AUTOSAR XML (schema 4-0-3)
package /ComponentTypes
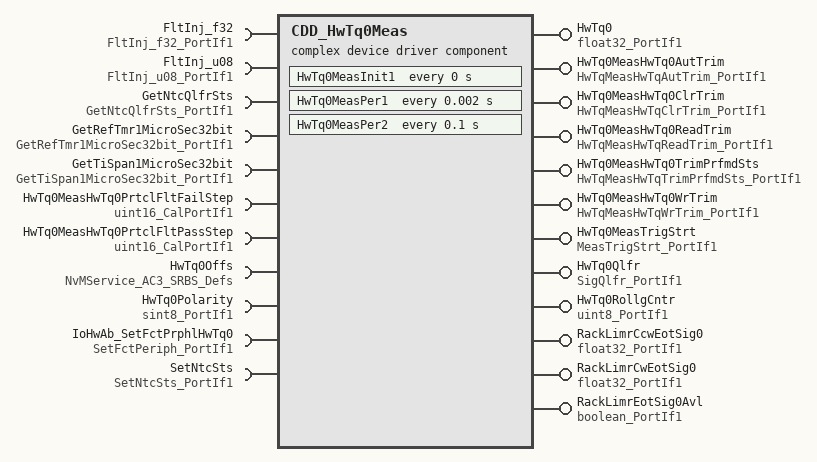
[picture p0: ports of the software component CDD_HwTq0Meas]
  complex device driver sw component type CDD_HwTq0Meas
    12 x provide port:
      HwTq0: nonqueued-sender-com-spec{data-element=Val, init-value=0}, provided-interface=float32_PortIf1
      HwTq0MeasHwTq0AutTrim: server-com-spec{operation=Oper, queue-length=1}, provided-interface=HwTqMeasHwTqAutTrim_PortIf1
      HwTq0MeasHwTq0ClrTrim: server-com-spec{operation=Oper, queue-length=1}, provided-interface=HwTqMeasHwTqClrTrim_PortIf1
      HwTq0MeasHwTq0ReadTrim: server-com-spec{operation=Oper, queue-length=1}, provided-interface=HwTqMeasHwTqReadTrim_PortIf1
      HwTq0MeasHwTq0TrimPrfmdSts: server-com-spec{operation=Oper, queue-length=1}, provided-interface=HwTqMeasHwTqTrimPrfmdSts_PortIf1
      HwTq0MeasHwTq0WrTrim: server-com-spec{operation=Oper, queue-length=1}, provided-interface=HwTqMeasHwTqWrTrim_PortIf1
      HwTq0MeasTrigStrt: server-com-spec{operation=Oper, queue-length=1}, provided-interface=MeasTrigStrt_PortIf1
      HwTq0Qlfr: nonqueued-sender-com-spec{data-element=Val, init-value=0}, provided-interface=SigQlfr_PortIf1
      HwTq0RollgCntr: nonqueued-sender-com-spec{data-element=Val, init-value=0}, provided-interface=uint8_PortIf1
      RackLimrCcwEotSig0: nonqueued-sender-com-spec{data-element=Val, init-value=0}, provided-interface=float32_PortIf1
      RackLimrCwEotSig0: nonqueued-sender-com-spec{data-element=Val, init-value=0}, provided-interface=float32_PortIf1
      RackLimrEotSig0Avl: nonqueued-sender-com-spec{data-element=Logl, init-value=0}, provided-interface=boolean_PortIf1
    11 x require port:
      FltInj_f32: required-interface=FltInj_f32_PortIf1
      FltInj_u08: required-interface=FltInj_u08_PortIf1
      GetNtcQlfrSts: required-interface=GetNtcQlfrSts_PortIf1
      GetRefTmr1MicroSec32bit: required-interface=GetRefTmr1MicroSec32bit_PortIf1
      GetTiSpan1MicroSec32bit: required-interface=GetTiSpan1MicroSec32bit_PortIf1
      HwTq0MeasHwTq0PrtclFltFailStep: parameter-require-com-spec{init-value=2521, parameter=Val}, required-interface=uint16_CalPortIf1
      HwTq0MeasHwTq0PrtclFltPassStep: parameter-require-com-spec{init-value=1000, parameter=Val}, required-interface=uint16_CalPortIf1
      HwTq0Offs: required-interface=NvMService_AC3_SRBS_Defs
      HwTq0Polarity: nonqueued-receiver-com-spec{data-element=Val, filter=data-filter-type=ALWAYS, init-value=1}, required-interface=sint8_PortIf1
      IoHwAb_SetFctPrphlHwTq0: required-interface=SetFctPeriph_PortIf1
      SetNtcSts: required-interface=SetNtcSts_PortIf1
    behavior CDD_HwTq0Meas_InternalBehavior: data-type-mapping=Nexteer
      ar-typed-per-instance-memorys:
        15 x data, all with sw-calibration-access=READ-ONLY:
          HwTq0ComStsErrCntr: type=uint8
          HwTq0IntSnsrErrCntr: type=uint8
          HwTq0MeasPrevHwTq0: type=float32
          HwTq0MeasPrevRollgCntr: type=uint8
          HwTq0MsgMissRxCnt: type=uint32
          HwTq0Offs: type=HwTqOffsRec1
          RackLimrCcwEot0: type=float32
          RackLimrCwEot0: type=float32
          RackLimrEot0Avl: type=boolean
          RackLimrEot0Data{0..2}: type=uint8
          RackLimrEot0Id{2..4}DataReadCmpl: type=boolean
      5 x operation invoked event:
        OIT_HwTq0MeasHwTq0AutTrim_Oper_HwTq0MeasHwTq0AutTrim_Oper: start-on-event=HwTq0MeasHwTq0AutTrim_Oper, operation=HwTq0MeasHwTq0AutTrim.Oper
        OIT_HwTq0MeasHwTq0ClrTrim_Oper_HwTq0MeasHwTq0ClrTrim_Oper: start-on-event=HwTq0MeasHwTq0ClrTrim_Oper, operation=HwTq0MeasHwTq0ClrTrim.Oper
        OIT_HwTq0MeasHwTq0ReadTrim_Oper_HwTq0MeasHwTq0ReadTrim_Oper: start-on-event=HwTq0MeasHwTq0ReadTrim_Oper, operation=HwTq0MeasHwTq0ReadTrim.Oper
        OIT_HwTq0MeasHwTq0TrimPrfmdSts_Oper_HwTq0MeasHwTq0TrimPrfmdSts_Oper: start-on-event=HwTq0MeasHwTq0TrimPrfmdSts_Oper, operation=HwTq0MeasHwTq0TrimPrfmdSts.Oper
        OIT_HwTq0MeasHwTq0WrTrim_Oper_HwTq0MeasHwTq0WrTrim_Oper: start-on-event=HwTq0MeasHwTq0WrTrim_Oper, operation=HwTq0MeasHwTq0WrTrim.Oper
      timing event CDD_HwTq0Meas_InitEvent: start-on-event=HwTq0MeasInit1, period=0
      timing event TMT_HwTq0MeasPer1: start-on-event=HwTq0MeasPer1, period=0.002
      timing event TMT_HwTq0MeasPer3: start-on-event=HwTq0MeasPer2, period=0.1
      operation invoked event OIT_HwTq0MeasTrigStrt_Oper_HwTq0MeasTrgStrt_Oper: start-on-event=HwTq0MeasTrigStrt_Oper, operation=HwTq0MeasTrigStrt.Oper
      9 x runnable:
        HwTq0MeasHwTq0AutTrim_Oper
          sync call SC_HwTq0Offs_SetRamBlockStatus: operation=HwTq0Offs.SetRamBlockStatus, timeout=0
        HwTq0MeasHwTq0ClrTrim_Oper
          sync call SC_HwTq0Offs_SetRamBlockStatus: operation=HwTq0Offs.SetRamBlockStatus, timeout=0
        HwTq0MeasHwTq0ReadTrim_Oper
        HwTq0MeasHwTq0TrimPrfmdSts_Oper
        HwTq0MeasHwTq0WrTrim_Oper
          sync call SC_HwTq0Offs_SetRamBlockStatus: operation=HwTq0Offs.SetRamBlockStatus, timeout=0
        HwTq0MeasInit1
          sync call SC_GetRefTmr1MicroSec32bit_Oper: operation=GetRefTmr1MicroSec32bit.Oper, timeout=0
          sync call SC_GetTiSpan1MicroSec32bit_Oper: operation=GetTiSpan1MicroSec32bit.Oper, timeout=0
          sync call SC_IoHwAb_SetFctPrphlHwTq0_Oper: operation=IoHwAb_SetFctPrphlHwTq0.Oper, timeout=0
        HwTq0MeasPer1
          data-receive-point-by-arguments:
            access REC_HwTq0Polarity_Val: accessed-variable=HwTq0Polarity.Val
          data-send-points:
            6 x access:
              SEND_HwTq0_Val: accessed-variable=HwTq0.Val
              SEND_HwTq0Qlfr_Val: accessed-variable=HwTq0Qlfr.Val
              SEND_HwTq0RollgCntr_Val: accessed-variable=HwTq0RollgCntr.Val
              SEND_RackLimrCcwEotSig0_Val: accessed-variable=RackLimrCcwEotSig0.Val
              SEND_RackLimrCwEotSig0_Val: accessed-variable=RackLimrCwEotSig0.Val
              SEND_RackLimrEotSig0Avl_Logl: accessed-variable=RackLimrEotSig0Avl.Logl
          4 x sync call, all with timeout=0:
            SC_FltInj_f32_Oper: operation=FltInj_f32.Oper
            SC_FltInj_u08_Oper: operation=FltInj_u08.Oper
            SC_GetNtcQlfrSts_Oper: operation=GetNtcQlfrSts.Oper
            SC_SetNtcSts_Oper: operation=SetNtcSts.Oper
        HwTq0MeasPer2
          sync call SC_SetNtcSts_Oper: operation=SetNtcSts.Oper, timeout=0
        HwTq0MeasTrigStrt_Oper
          sync call SC_GetRefTmr1MicroSec32bit_Oper: operation=GetRefTmr1MicroSec32bit.Oper, timeout=0
          sync call SC_GetTiSpan1MicroSec32bit_Oper: operation=GetTiSpan1MicroSec32bit.Oper, timeout=0
      swc service dependency NvmHwTq0Offs: assigned-datas=[{role=ramBlock, used-data-element=HwTq0Offs}, {role=defaultValue, used-parameter-element=HwTq0OffsDft}]
        assigned-ports:
          port-prototype=HwTq0Offs, role=NvMService_AC3_SRBS_Defs
          port-prototype=HwTq0Offs, role=NvMService_AC3_SRBS_Defs
        service-needs:
          nv block needs NvmHwTq0Offs: n-data-sets=0, readonly=false, reliability=ERROR-DETECTION, resistant-to-changed-sw=true, restore-at-start=true, store-at-shutdown=true, write-only-once=false, writing-frequency=0, writing-priority=LOW
      shared-parameters:
        parameter data prototype HwTq0OffsDft: sw-calibration-access=READ-WRITE, type=HwTqOffsRec1, init-value=fields=[OffsTrim:0, OffsTrimPrfmdSts:0]
  swc implementation CDD_HwTq0Meas_Implementation: behavior=CDD_HwTq0Meas_InternalBehavior
    code-descriptors:
      code Default: artifact-descriptors=autosar-engineering-object={short-label=Default, category=SWSRC}
